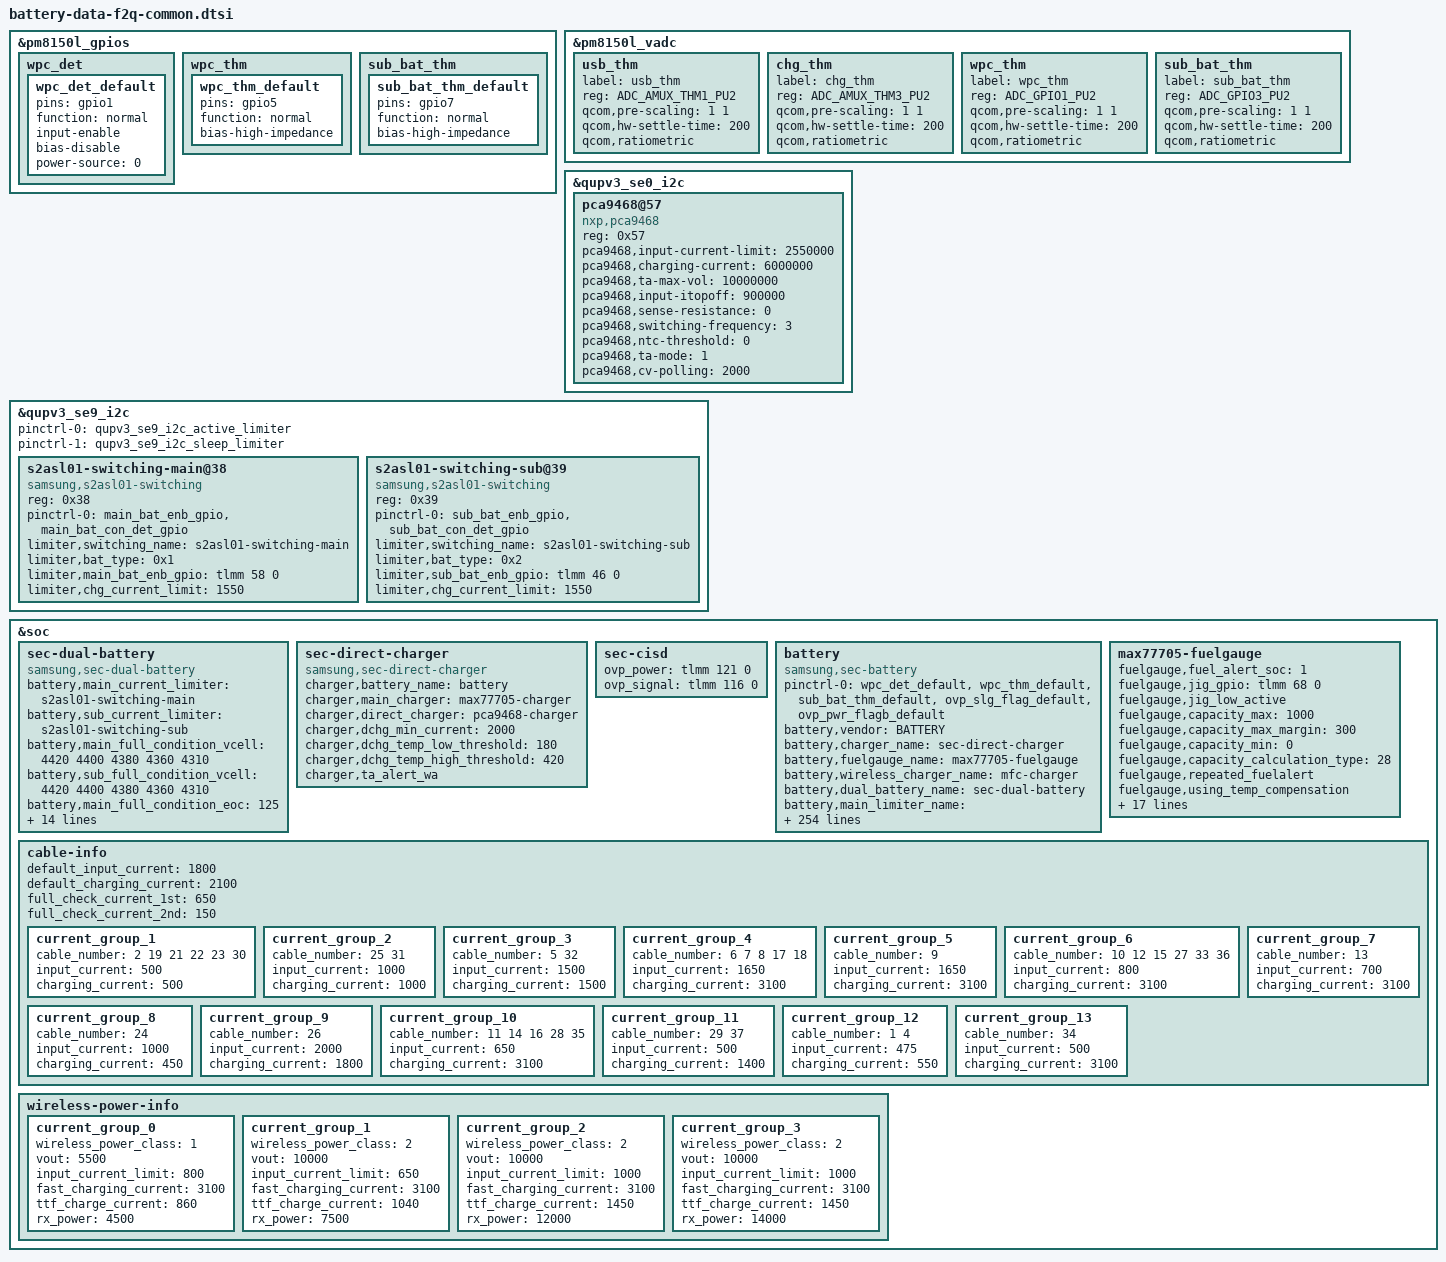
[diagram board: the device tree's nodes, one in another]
/* Copyright (c) 2014, The Linux Foundation. All rights reserved.
 *
 * This program is free software; you can redistribute it and/or modify
 * it under the terms of the GNU General Public License version 2 and
 * only version 2 as published by the Free Software Foundation.
 *
 * This program is distributed in the hope that it will be useful,
 * but WITHOUT ANY WARRANTY; without even the implied warranty of
 * MERCHANTABILITY or FITNESS FOR A PARTICULAR PURPOSE.  See the
 * GNU General Public License for more details.
 */

#include "battery-rx-data-f2q-idt.dtsi"

&pm8150l_gpios {
	wpc_det { /* WPC_DET */
		wpc_det_default: wpc_det_default {
			pins = "gpio1";
			function = "normal";
			input-enable;
			bias-disable;
			power-source = <0>;
		};
	};
	wpc_thm { /* GPIO_05 */
		wpc_thm_default: wpc_thm_default {
			pins = "gpio5";
			function = "normal";
			bias-high-impedance;
		};
	};
	sub_bat_thm { /* GPIO_07 */
		sub_bat_thm_default: sub_bat_thm_default {
			pins = "gpio7";
			function = "normal";
			bias-high-impedance;
		};
	};
};

&pm8150l_vadc {
	usb_thm { /* AMUX_1 */
		label = "usb_thm";
		reg = <ADC_AMUX_THM1_PU2>;
		qcom,pre-scaling = <1 1>;
		qcom,hw-settle-time = <200>;
		qcom,ratiometric;
	};
	chg_thm { /* AMUX_3 */
		label = "chg_thm";
		reg = <ADC_AMUX_THM3_PU2>;
		qcom,pre-scaling = <1 1>;
		qcom,hw-settle-time = <200>;
		qcom,ratiometric;
	};
	wpc_thm { /* GPIO_05 */
		label = "wpc_thm";
		reg = <ADC_GPIO1_PU2>;
		qcom,pre-scaling = <1 1>;
		qcom,hw-settle-time = <200>;
		qcom,ratiometric;
	};
	sub_bat_thm { /* GPIO_07 */
		label = "sub_bat_thm";
		reg = <ADC_GPIO3_PU2>;
		qcom,pre-scaling = <1 1>;
		qcom,hw-settle-time = <200>;
		qcom,ratiometric;
	};
};

&qupv3_se0_i2c {
	status = "okay";

	pca9468@57 {
		compatible = "nxp,pca9468";
		reg = <0x57>;
		pca9468,input-current-limit = <2550000>; /* 2.55A */
		pca9468,charging-current = <6000000>; /* 6A */
		pca9468,ta-max-vol = <10000000>; /* 10.0V */
		pca9468,input-itopoff = <900000>; /* 900mA */
		pca9468,sense-resistance = <0>; /* 5mOhm */
		pca9468,switching-frequency = <3>; /* 980KHz */
		pca9468,ntc-threshold = <0>; /* disable */
		pca9468,ta-mode = <1>; /* 2:1 charging mode */
		pca9468,cv-polling = <2000>; /* 2s */
	};
};

&qupv3_se9_i2c {
	status = "okay";

	pinctrl-0 = <&qupv3_se9_i2c_active_limiter>;
	pinctrl-1 = <&qupv3_se9_i2c_sleep_limiter>;

	s2asl01-switching-main@38 {
		compatible = "samsung,s2asl01-switching";
		reg = <0x38>;
		status = "okay";

		pinctrl-names = "default";
		pinctrl-0 = <&main_bat_enb_gpio &main_bat_con_det_gpio>;
		limiter,switching_name = "s2asl01-switching-main";
		limiter,bat_type = <0x1>; /* LIMITER_MAIN */
		limiter,main_bat_enb_gpio = <&tlmm 58 0>; /* MAIN_BATTERY_SW_ENB_AP */
		limiter,chg_current_limit = <1550>;
	};
	s2asl01-switching-sub@39 {
		compatible = "samsung,s2asl01-switching";
		reg = <0x39>;
		status = "okay";

		pinctrl-names = "default";
		pinctrl-0 = <&sub_bat_enb_gpio &sub_bat_con_det_gpio>;
		limiter,switching_name = "s2asl01-switching-sub";
		limiter,bat_type = <0x2>; /* LIMITER_SUB */
		limiter,sub_bat_enb_gpio = <&tlmm 46 0>; /* SUB_BATTERY_SW_ENB */
		limiter,chg_current_limit = <1550>;
	};
};

&soc {
	sec-dual-battery {
		status = "okay";
		compatible = "samsung,sec-dual-battery";

		battery,main_current_limiter = "s2asl01-switching-main";
		battery,sub_current_limiter = "s2asl01-switching-sub";
		battery,main_full_condition_vcell = <4420 4400 4380 4360 4310>;
		battery,sub_full_condition_vcell = <4420 4400 4380 4360 4310>;
		battery,main_full_condition_eoc = <125>;
		battery,sub_full_condition_eoc = <125>;
		battery,main_bat_con_det_gpio = <&tlmm 9 0>; /* MAIN_BATTERY_CON_DET_N */
		battery,sub_bat_con_det_gpio = <&tlmm 77 0>; /* SUB_BATTERY_CON_DET_N */
		battery,main_bat_enb_gpio = <&tlmm 58 0>; /* MAIN_BATTERY_SW_ENB_AP */
		battery,sub_bat_enb_gpio = <&tlmm 46 0>; /* SUB_BATTERY_SW_ENB */
		battery,main_charging_rate = <65>;
		battery,sub_charging_rate = <70>;
		battery,dc_main_charging_rate = <49>;
		battery,dc_sub_charging_rate = <57>;
		battery,force_recharge_margin = <140>;
		battery,max_main_charging_current = <3150>;
		battery,min_main_charging_current = <200>;
		battery,max_sub_charging_current = <3150>;
		battery,min_sub_charging_current = <200>;
	};

	sec-direct-charger {
		status = "okay";
		compatible = "samsung,sec-direct-charger";

		charger,battery_name = "battery";
		charger,main_charger = "max77705-charger";
		charger,direct_charger = "pca9468-charger";

		charger,dchg_min_current = <2000>;
		charger,dchg_temp_low_threshold = <180>;
		charger,dchg_temp_high_threshold = <420>;

		charger,ta_alert_wa;
	};

	sec-cisd {
		ovp_power = <&tlmm 121 0>;
		ovp_signal = <&tlmm 116 0>;
	};

	battery {
		status = "okay";
		compatible = "samsung,sec-battery";
		pinctrl-names = "default";
		pinctrl-0 = <&wpc_det_default &wpc_thm_default &sub_bat_thm_default &ovp_slg_flag_default &ovp_pwr_flagb_default>;
		battery,vendor = "BATTERY";
		battery,charger_name = "sec-direct-charger";
		battery,fuelgauge_name = "max77705-fuelgauge";
		battery,wireless_charger_name = "mfc-charger";
		battery,dual_battery_name = "sec-dual-battery";
		battery,main_limiter_name = "s2asl01-switching-main";
		battery,sub_limiter_name = "s2asl01-switching-sub";

		battery,technology = <2>; /* POWER_SUPPLY_TECHNOLOGY_LION */
		battery,fgsrc_switch_name = "max77705-charger"; /* Fuelgauge voltage source */
		battery,support_dual_battery = <1>;

		battery,chip_vendor = "QCOM";
		battery,temp_adc_type = <1>; /* SEC_BATTERY_ADC_TYPE_AP */

		battery,temp_check_type = <1>; /* SEC_BATTERY_TEMP_CHECK_ADC */
		battery,usb_temp_check_type = <1>;
		battery,chg_temp_check_type = <1>;
		battery,sub_bat_temp_check_type = <1>;
		battery,wpc_temp_check_type = <1>;
		battery,dchg_temp_check_type = <1>;

		battery,thermal_source = <2>; /* SEC_BATTERY_THERMAL_SOURCE_ADC */
		battery,usb_thermal_source = <2>; /* SEC_BATTERY_THERMAL_SOURCE_ADC */
		battery,chg_thermal_source = <2>; /* SEC_BATTERY_THERMAL_SOURCE_ADC */
		battery,sub_bat_thermal_source = <2>; /* SEC_BATTERY_THERMAL_SOURCE_ADC */
		battery,dchg_thermal_source = <3>; /* SEC_BATTERY_THERMAL_SOURCE_CHG_ADC */
		battery,wpc_thermal_source = <2>; /* SEC_BATTERY_THERMAL_SOURCE_ADC */

		battery,polling_time = <10 30 30 30 3600>;

		battery,temp_table_adc = <147080 169095 195198 226707 263040
						305427 354757 411656 478222 552638
						636353 728762 829087 934493 1042819
						1151621 1258369 1358736 1449048 1530557
						1599567 1659580 1690894>;
		battery,temp_table_data = <900 850 800 750 700
						650 600 550 500 450
						400 350 300 250 200
						150 100 50 0 (-50)
						(-100) (-150) (-200)>;

		battery,usb_temp_table_adc = <130903 153243 179909 211872 248983
						292149 342430 399934 467647 543252
						627875 721647 823313 930341 1040592
						1151361 1260012 1362218 1455752 1538451
						1609061 1668598 1717040>;
		battery,usb_temp_table_data = <900 850 800 750 700
						650 600 550 500 450
						400 350 300 250 200
						150 100 50 0 (-50)
						(-100) (-150) (-200)>;

		battery,chg_temp_table_adc = <118879 141197 168490 199956 236613
						278740 328632 385423 451946 527011
						611374 704714 806076 913321 1023831
						1133736 1242171 1344657 1438516 1522426
						1594852 1646539 1703827>;
		battery,chg_temp_table_data = <900 850 800 750 700
						650 600 550 500 450
						400 350 300 250 200
						150 100 50 0 (-50)
						(-100) (-150) (-200)>;

		battery,sub_bat_temp_table_adc = <128330 150886 177486 209385 246171
						289467 339748 397447 465376 540830
						626146 720501 822664 929822 1039921
						1149350 1257958 1356790 1450907 1532633
						1601210 1656466 1701080>;
		battery,sub_bat_temp_table_data = <900 850 800 750 700
						650 600 550 500 450
						400 350 300 250 200
						150 100 50 0 (-50)
						(-100) (-150) (-200)>;

		battery,dchg_temp_table_adc = <107916 129030 154836 185334 220524
						260406 307326 363630 426972 497352
						579462 668610 767142 870366 978282
						1083852 1189422 1290300 1381794 1463904
						1534284 1590588 1639854>;
		battery,dchg_temp_table_data = <900 850 800 750 700
						650 600 550 500 450
						400 350 300 250 200
						150 100 50 0 (-50)
						(-100) (-150) (-200)>;

		battery,wpc_temp_table_adc = <147080 169095 195198 226707 263040
						305427 354757 411656 478222 552638
						636353 728762 829087 934493 1042819
						1151621 1258369 1358736 1449048 1530557
						1599567 1659580 1690894>;
		battery,wpc_temp_table_data = <900 850 800 750 700
						650 600 550 500 450
						400 350 300 250 200
						150 100 50 0 (-50)
						(-100) (-150) (-200)>;

		battery,wireless_cc_cv = <85>;
		battery,wpc_det = <&pm8150l_gpios 1 GPIO_ACTIVE_HIGH>; /* WPC_DET */
		battery,wpc_en = <&tlmm 127 0>; /* WPC_EN */
		battery,mst_pwr_en = <&expander_gpios 4 0>; /* MST_PWR_EN */
		battery,adc_check_count = <5>;

		battery,cable_check_type = <4>; /* SEC_BATTERY_CABLE_CHECK_PSY */
		battery,cable_source_type = <1>; /* SEC_BATTERY_CABLE_SOURCE_EXTERNAL */
		battery,polling_type = <1>; /* SEC_BATTERY_MONITOR_ALARM */
		battery,monitor_initial_count = <0>;

		battery,battery_check_type = <0>; /* SEC_BATTERY_CHECK_NONE */

		battery,ovp_uvlo_check_type = <3>; /* SEC_BATTERY_OVP_UVLO_CHGPOLLING */

		battery,temp_check_count = <1>;
		battery,temp_highlimit_threshold_event = <700>;
		battery,temp_highlimit_recovery_event = <680>;
		battery,temp_high_threshold_event = <500>;
		battery,temp_high_recovery_event = <480>;
		battery,temp_low_threshold_event = <0>;
		battery,temp_low_recovery_event = <20>;
		battery,temp_highlimit_threshold_normal = <700>;
		battery,temp_highlimit_recovery_normal = <680>;
		battery,temp_high_threshold_normal = <500>;
		battery,temp_high_recovery_normal = <480>;
		battery,temp_low_threshold_normal = <0>;
		battery,temp_low_recovery_normal = <20>;
		battery,temp_highlimit_threshold_lpm = <700>;
		battery,temp_highlimit_recovery_lpm = <680>;
		battery,temp_high_threshold_lpm = <500>;
		battery,temp_high_recovery_lpm = <480>;
		battery,temp_low_threshold_lpm = <0>;
		battery,temp_low_recovery_lpm = <20>;
		battery,wpc_high_threshold_normal = <450>;
		battery,wpc_high_recovery_normal = <430>;
		battery,wpc_low_threshold_normal = <0>;
		battery,wpc_low_recovery_normal = <20>;
		battery,tx_high_threshold = <450>;
		battery,tx_high_recovery = <400>;
		battery,tx_low_threshold = <0>;
		battery,tx_low_recovery = <50>;
		battery,full_check_type = <2>; /* SEC_BATTERY_FULLCHARGED_FG_CURRENT */
		battery,full_check_type_2nd = <8>; /* SEC_BATTERY_FULLCHARGED_LIMITER */
		battery,full_check_count = <1>;

		battery,chg_high_temp = <450>;
		battery,chg_high_temp_recovery = <430>;
		battery,dchg_high_temp = <450>;
		battery,dchg_high_temp_recovery = <430>;
		battery,dchg_high_batt_temp = <400>;
		battery,dchg_high_batt_temp_recovery = <380>;
		battery,chg_input_limit_current = <1000>;
		battery,chg_charging_limit_current = <1800>;
		battery,dchg_input_limit_current = <1000>;
		battery,dchg_charging_limit_current = <2000>;

		battery,charging_limit_by_tx_check = <1>;
		battery,charging_limit_current_by_tx = <300>;
		battery,wpc_input_limit_by_tx_check = <1>;
		battery,wpc_input_limit_current_by_tx = <450>;
		battery,non_wc20_wpc_charging_limit = <1>;
		battery,non_wc20_wpc_high_temp = <390>;
		battery,non_wc20_wpc_high_temp_recovery = <380>;

		battery,wpc_temp_control_source = <1>; /* TEMP_CONTROL_SOURCE_BAT_THM = WPC_THM */
		battery,wpc_high_temp = <375>;
		battery,wpc_high_temp_recovery = <365>;
		battery,wpc_input_limit_current = <450>;
		battery,wpc_charging_limit_current = <1000>;
		battery,wpc_temp_lcd_on_control_source = <1>; /* TEMP_CONTROL_SOURCE_BAT_THM = WPC_THM */
		battery,wpc_lcd_on_high_temp = <375>;
		battery,wpc_lcd_on_high_temp_rec = <365>;
		battery,wpc_lcd_on_input_limit_current = <450>;

		battery,wpc_store_high_temp = <360>;
		battery,wpc_store_high_temp_recovery = <340>;
		battery,wpc_store_charging_limit_current = <400>;
		battery,wpc_store_lcd_on_high_temp = <360>;
		battery,wpc_store_lcd_on_high_temp_rec = <300>;
		battery,wpc_store_lcd_on_charging_limit_current = <400>;
		battery,store_mode_buckoff;

		battery,ta_alert_wa;

		battery,sleep_mode_limit_current = <800>;
		battery,wc_full_input_limit_current = <100>;

		battery,mix_high_temp = <420>;
		battery,mix_high_chg_temp = <500>;
		battery,mix_high_temp_recovery = <390>;

		battery,full_condition_type = <9>; /* SEC_BATTERY_FULL_CONDITION_NOTIMEFULL | SEC_BATTERY_FULL_CONDITION_VCELL */
		battery,full_condition_soc = <93>;
		battery,full_condition_vcell = <4370>;

		battery,recharge_check_count = <1>;
		battery,recharge_condition_type = <8>; /* SEC_BATTERY_RECHARGE_CONDITION_LIMITER */
		battery,recharge_condition_soc = <98>;
		battery,recharge_condition_vcell = <4350>;

		battery,charging_reset_time = <0>;

		battery,chg_float_voltage = <4420>;
		battery,chg_ocp_current = <6200>;
		battery,chg_ocp_dtc = <100>;
		battery,topoff_time = <70>;

		battery,pre_afc_work_delay = <2000>;
		battery,pre_wc_afc_work_delay = <4000>;
		battery,pre_afc_input_current = <500>;
		battery,pre_wc_afc_input_current = <500>;
		battery,prepare_ta_delay = <0>; /* msec */

		battery,swelling_high_temp_block = <420>;
		battery,swelling_high_temp_recov = <400>;
		battery,swelling_wc_high_temp_block = <420>;
		battery,swelling_wc_high_temp_recov = <400>;
		battery,swelling_low_temp_block_1st = <150>;
		battery,swelling_low_temp_recov_1st = <170>;
		battery,swelling_low_temp_block_2nd = <50>;
		battery,swelling_low_temp_recov_2nd = <70>;
		battery,swelling_low_temp_3rd_ctrl;
		battery,swelling_low_temp_block_3rd = <180>;
		battery,swelling_low_temp_recov_3rd = <200>;

		battery,swelling_low_temp_current = <900>;	/* 0.24C */
		battery,swelling_low_temp_current_2nd = <350>;	/* 0.1C */
		battery,swelling_low_temp_current_3rd = <2950>;	/* 0.72C */
		battery,swelling_low_temp_topoff = <218>;	/* 0.05C */
		battery,swelling_high_temp_current = <1450>;	/* 0.36C */
		battery,swelling_high_temp_topoff = <218>;	/* 0.05C */
		battery,swelling_wc_high_temp_current = <900>;	/* 0.24C */
		battery,swelling_wc_low_temp_current = <900>;	/* 0.24C */
		battery,swelling_wc_low_temp_current_2nd = <350>;	/* 0.1C */
		battery,swelling_wc_low_temp_current_3rd = <2950>;	/* 0.72C */
		/* parameters for using limiter */
		battery,swelling_main_high_temp_current = <750>;	/* 0.36C */
		battery,swelling_sub_high_temp_current = <800>;		/* 0.36C */
		battery,swelling_main_low_temp_current = <500>;		/* 0.24C */
		battery,swelling_sub_low_temp_current = <550>;		/* 0.24C */
		battery,swelling_main_low_temp_current_2nd = <200>;	/* 0.1C */
		battery,swelling_sub_low_temp_current_2nd = <200>;	/* 0.1C */
		battery,swelling_main_low_temp_current_3rd = <1500>;	/* 0.72C */
		battery,swelling_sub_low_temp_current_3rd = <1600>;	/* 0.72C */

		battery,swelling_drop_float_voltage = <4200>;
		battery,swelling_high_rechg_voltage = <4050>;
		battery,swelling_low_rechg_thr = <150>;

		battery,siop_input_limit_current = <1200>;
		battery,siop_charging_limit_current = <1800>;
		battery,siop_hv_input_limit_current = <700>;
		battery,siop_hv_input_limit_current_2nd = <450>;
		battery,siop_hv_charging_limit_current = <1000>;
		battery,siop_apdo_input_limit_current = <1000>;
		battery,siop_apdo_charging_limit_current = <2000>;

		battery,siop_wireless_input_limit_current = <700>;
		battery,siop_wireless_charging_limit_current = <1000>;
		battery,siop_hv_wireless_input_limit_current = <700>;
		battery,siop_hv_wireless_charging_limit_current = <1000>;
		battery,siop_store_hv_wireless_input_limit_current = <450>;

		battery,wireless_otg_input_current = <900>;

		battery,ttf_hv_charge_current = <2600>;
		battery,ttf_hv_wireless_charge_current = <1040>;
		battery,ttf_wireless_charge_current = <860>;
		battery,ttf_dc25_charge_current = <3500>;

		battery,rp_current_rp1 = <500>;
		battery,rp_current_rp2 = <1500>;
		battery,rp_current_rp3 = <3000>;
		battery,rp_current_rdu_rp3 = <2100>;
		battery,rp_current_abnormal_rp3 = <1800>;

		battery,pd_charging_charge_power = <15000>;
		battery,max_charging_current = <3100>;
		battery,max_charging_charge_power = <25000>; /* 25W */

		/* cycle, chg_float_voltage, recharge_condition_vcell, full_condition_vcell, full_condition_soc */
		battery,age_data = <0 4420 4350 4370 93
				300 4400 4330 4350 92
				400 4380 4310 4330 91
				700 4360 4290 4310 90
				1000 4310 4240 4260 89>;

		battery,health_condition = <
			/* CYCLE ASOC */
			900 75	/* GOOD */
			1200 65 /* NORMAL */
			1500 55 /* AGED */
			>;

		/* step charging option */
		battery,step_charging_type = <0>;

		/* direct step charging option */
		battery,dc_step_chg_type = <0xA9>; /* STEP_CHARGING_CONDITION_SOC_INIT_ONLY, STEP_CHARGING_CONDITION_FLOAT_VOLTAGE, STEP_CHARGING_CONDITION_ONLINE, STEP_CHARGING_CONDITION_VOLTAGE*/
		battery,dc_step_chg_charge_power = <22000>;
		battery,dc_step_chg_step = <3>;
		battery,dc_step_chg_cond_vol = <4000 4200 4420>; /*<25w 3step> STEP_CHARGING_CONDITION_VOLTAGE */
		battery,dc_step_chg_iin_check_cnt = <3>;
		battery,dc_step_chg_cond_soc = <25 45 100
						25 45 100
						25 45 100
						25 45 100
						25 45 100>; /* <25w 3step> STEP_CHARGING_CONDITION_SOC */
		battery,dc_step_chg_val_vfloat = <4420 4420 4420>; /* <25w 3step> STEP_CHARGING_CONDITION_FLOAT_VOLTAGE */
		battery,dc_step_chg_val_iout = <4800 3900 3400>; /* <25w 3step> */

		battery,main_cell_margin_cc = <100>;
		battery,main_cell_margin_cv = <30>;

		battery,snkcap_data = /bits/ 8 <0x04 0x2C 0x91 0x01 0x36 0xC8 0xD0 0x02 0x00 0xC8 0x90
								0x41 0x8B 0x30 0x21 0xDC 0xC0>;


		battery,max_input_voltage = <9000>; /* mV */
		battery,max_input_current = <3000>; /* mA */

		battery,enable_sysovlo_irq;
		battery,enable_noise_wa;
		battery,dis_auto_shipmode_temp_ctrl;

		battery,standard_curr = <3400>; /* same as 3step iout */
		battery,expired_time = <9720>; /* 102min + margin 60min */
		battery,recharging_expired_time = <5400>;

		battery,battery_full_capacity = <4500>;
		battery,cisd_max_voltage_thr = <4500>; /* batttery ovp dettection voltage */
		battery,cisd_alg_index = <8>;
		battery,ignore_cisd_index = <0 0>;
		battery,ignore_cisd_index_d = <0 80>; /* Do not use AFC_FAIL_PER_DAY to DROP_VALUE_PER_DAY */ 

		battery,tx_stop_capacity = <30>;
		battery,tx_minduty_default = <20>;
		battery,tx_minduty_5V = <50>;

		battery,tx_uno_vout = <5>; /* WC_TX_VOUT_7_5V */
		battery,tx_gear_vout = <0>; /* WC_TX_VOUT_5_0V */
		battery,tx_uno_iout = <1500>;
		battery,tx_mfc_iout_gear = <1500>;
		battery,tx_mfc_iout_phone = <1100>;
		battery,tx_mfc_iout_phone_5v = <300>;
		battery,tx_mfc_iout_lcd_on = <900>;

		io-channels = <&pm8150l_vadc ADC_GPIO1_PU2>, <&pm8150l_vadc ADC_AMUX_THM3_PU2>, <&pm8150l_vadc ADC_GPIO1_PU2>, <&pm8150l_vadc ADC_AMUX_THM1_PU2>, <&pm8150l_vadc ADC_GPIO3_PU2>;
		io-channel-names = "adc-temp", "adc-chg-temp", "adc-wpc-temp", "adc-usb-temp", "adc-sub-bat";
	};

	max77705-fuelgauge {
		/* for 4375mAh battery */
		status = "okay";
		fuelgauge,fuel_alert_soc = <1>;
		fuelgauge,jig_gpio = <&tlmm 68 0>; /* IFC_SENSE_INT_AP */
		fuelgauge,jig_low_active;
		fuelgauge,capacity_max = <1000>;
		fuelgauge,capacity_max_margin = <300>;
		fuelgauge,capacity_min = <0>;
		fuelgauge,capacity_calculation_type = <28>;
		fuelgauge,repeated_fuelalert;
		fuelgauge,using_temp_compensation;
		fuelgauge,low_temp_limit = <100>;
		fuelgauge,vempty_recover_time = <180>; /* 3 mins */
		fuelgauge,using_hw_vempty;
		fuelgauge,v_empty = <0xA7E2>; /* Empty: 3350mV, Recover: 3920mV */
		fuelgauge,v_empty_origin = <0x7D54>; /* Empty: 2500mV, Recover: 3360mV */
		fuelgauge,sw_v_empty_voltage = <3200>;
		fuelgauge,sw_v_empty_voltage_cisd = <3100>;
		fuelgauge,sw_v_empty_recover_voltage = <3480>;
		fuelgauge,fg_resistor = <2>;
		fuelgauge,capacity = <0x0fa2>; /* capacity = fullcapnom = DesignCap */
		fuelgauge,fg_reset_wa_data = <0x0fa2 0x3200 0x03e8 0x0045 0x1526>; /* fullcapnom(=capacity), dPacc, dQacc,  rcomp0, tempco */
		fuelgauge,discharge_temp_threshold = <600>;
		fuelgauge,discharge_volt_threshold = <4200>;
		fuelgauge,ttf_capacity = <3700>;
		fuelgauge,cv_data = <
			3241	837	1673
			2761	845	1639
			2715	855	1586
			2543	869	1524
			2467	872	1493
			2366	883	1462
			2203	892	1399
			2085	893	1357
			2033	899	1337
			1763	912	1213
			1484	929	1060
			1261	943	907
			1074	955	754
			950	965	603
			854	972	502
			747	980	351
			660	987	200
			600	994	49
			560	1000	0
			>;
	};

/* sec_battery_cable
 *   0	UNKNOWN,
 *   1	NONE,
 *   2	PREPARE_TA,
 *   3	TA,
 *   4	USB,
 *   5	USB_CDP,
 *   6	9V_TA,
 *   7	9V_ERR,
 *   8	9V_UNKNOWN,
 *   9	12V_TA,
 *  10	WIRELESS,
 *  11	HV_WIRELESS,
 *  12	PMA_WIRELESS,
 *  13	WIRELESS_PACK,
 *  14	CABLE_WIRELESS_HV_PACK,
 *  15	WIRELESS_STAND,
 *  16	WIRELESS_HV_STAND,
 *  17	QC20,
 *  18	QC30,
 *  19	PDIC,
 *  20	UARTOFF,
 *  21	OTG,
 *  22	LAN_HUB,
 *  23	POWER_SHARING,
 *  24	HMT_CONNECTED,
 *  25	HMT_CHARGE,
 *  26	HV_TA_CHG_LIMIT,
 *  27	WIRELESS_VEHICLE,
 *  28	WIRELESS_HV_VEHICLE,
 *  29	PREPARE_WIRELESS_HV,
 *  30  TIMEOUT,
 *  31  SMART_OTG,
 *  32  SMART_NOTG,
 *  33  WIRELESS_TX,
 *  34	HV_WIRELESS_20,
 *  35	HV_WIRELESS_20_LIMIT,
 *  36	WIRELESS_FAKE,
 *  37  PREPARE_WIRELESS_20,
 *  38	CABLE_PDIC_APDO,
 *  39	CABLE_MAX,
 */
	cable-info {
		default_input_current = <1800>;
		default_charging_current = <2100>;
		full_check_current_1st = <650>;
		full_check_current_2nd = <150>;

		current_group_1 {
			cable_number = <2 19 21 22 23 30>;
			input_current = <500>;
			charging_current = <500>;
		};
		current_group_2 {
			cable_number = <25 31>;
			input_current = <1000>;
			charging_current = <1000>;
		};
		current_group_3 {
			cable_number = <5 32>;
			input_current = <1500>;
			charging_current = <1500>;
		};
		current_group_4 {
			cable_number = <6 7 8 17 18>;
			input_current = <1650>;
			charging_current = <3100>;
		};
		current_group_5 {
			cable_number = <9>;
			input_current = <1650>;
			charging_current = <3100>;
		};
		current_group_6 {
			cable_number = <10 12 15 27 33 36>;
			input_current = <800>;
			charging_current = <3100>;
		};
		current_group_7 {
			cable_number = <13>;
			input_current = <700>;
			charging_current = <3100>;
		};
		current_group_8 {
			cable_number = <24>;
			input_current = <1000>;
			charging_current = <450>;
		};
		current_group_9 {
			cable_number = <26>;
			input_current = <2000>;
			charging_current = <1800>;
		};
		current_group_10 {
			cable_number = <11 14 16 28 35>;
			input_current = <650>;
			charging_current = <3100>;
		};
		current_group_11 {
			cable_number = <29 37>;
			input_current = <500>;
			charging_current = <1400>;
		};
		current_group_12 {
			cable_number = <1 4>;
			input_current = <475>;
			charging_current = <550>;
		};
		current_group_13 {
			cable_number = <34>;
			input_current = <500>;
			charging_current = <3100>;
		};
	};
	wireless-power-info {
		current_group_0 {
			wireless_power_class = <1>;
			vout = <5500>;
			input_current_limit = <800>;
			fast_charging_current = <3100>;
			ttf_charge_current = <860>;
			rx_power = <4500>;
		};
		current_group_1 {
			wireless_power_class = <2>;
			vout = <10000>;
			input_current_limit = <650>;
			fast_charging_current = <3100>;
			ttf_charge_current = <1040>;
			rx_power = <7500>;
		};
		current_group_2 {
			wireless_power_class = <2>;
			vout = <10000>;
			input_current_limit = <1000>;
			fast_charging_current = <3100>;
			ttf_charge_current = <1450>;
			rx_power = <12000>;
		};
		current_group_3 {
			wireless_power_class = <2>;
			vout = <10000>;
			input_current_limit = <1000>;
			fast_charging_current = <3100>;
			ttf_charge_current = <1450>;
			rx_power = <14000>;
		};
	};
};
